# MIMXRT1042 register map
Vendor: nxp.com; File version: 1.0
CPU: CM7 r0p1, little endian, MPU, FPU, VTOR, 4 interrupt priority bits
Registers are 32-bit, read-write, reset 0x0 unless marked. A register's access mark holds for its fields unless they carry their own. Offsets are from the block's base; [hi:lo] are bit positions; {n}, {i} and the like mark numbered series; 'fields as' and 'values as' point back to an identical list.

## MPU — Memory Protection Unit
Base 0xE000ED90
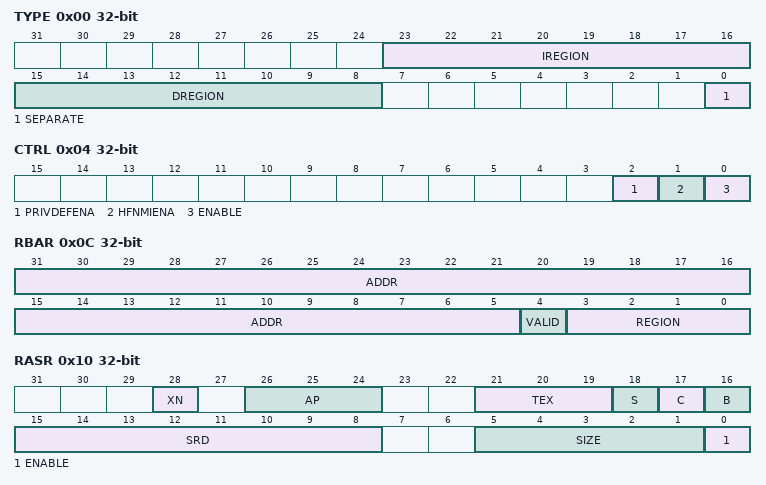
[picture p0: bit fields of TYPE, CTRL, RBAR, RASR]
0x00 TYPE ro reset not defined — The MPU Type Register indicates how many regions the MPU support. Software can use it to determine if the processor implements an MPU.
  [23:16] IREGION — Instruction region. RAZ. Armv7-M only supports a unified MPU.
  [15:8] DREGION — Number of regions supported by the MPU. If this field reads-as-zero the processor does not implement an MPU.
  [0] SEPARATE — Indicates support for separate instruction and data address maps. RAZ. Armv7-M only supports a unified MPU
0x04 CTRL — MPU Control Register.
  [2] PRIVDEFENA
    0=ENABLE (Disables the default memory map. Any instruction or data access that does not access a defined region faults.); 1=DISABLE (Enables the default memory map as a background region for privileged access. The background region acts as region number -1. All memory regions configured in the MPU take priority over the default memory map.)
  [1] HFNMIENA — Controls whether handlers executing with priority less than 0 access memory with the MPU enabled or with the MPU disabled.
    0=DISABLE (Disables the MPU for these handlers.); 1=ENABLE (Use the MPU for memory accesses by these handlers.)
  [0] ENABLE — Enables the MPU.
    0=MPU_DISABLE (The MPU is disabled.); 1=MPU_ENABLED (The MPU is enabled.)
0x08 RNR reset not defined — MPU Region Number Register.
  [7:0] REGION — Indicates the memory region accessed by MPU_RBAR and MPU_RASR.
0x0C RBAR reset not defined — MPU Region Base Address Register.
  [31:5] ADDR — Base address of the region.
  [4] VALID — On writes, indicates whether the region to update is specified by MPU_RNR.REGION, or by the REGION value specified in this write. When using the REGION value specified by this write, MPU_RNR.REGION is updated to this value.
    0=IGNORE_RBAR_REGION (Apply the base address update to the region specified by MPU_RNR.REGION. The REGION field value is ignored.); 1=USE_RBAR_REGION (Update MPU_RNR.REGION to the value obtained by zero extending the REGION value specified in this write, and apply the base address update to this region.)
  [3:0] REGION — On writes, can specify the number of the region to update. On reads, returns bits[3:0] of MPU_RNR.
0x10 RASR reset not defined — MPU Region Attribute and Size Register.
  [28] XN — The XN bit is an Execute Never bit, that indicates whether the processor can execute instructions from the region.
    0=EXECUTE (Execution of an instruction fetched from this region permitted.); 1=EXECUTE_NEVER (Execution of an instruction fetched from this region not permitted.)
  [26:24] AP — The AP[2:0] bits indicate the access and privilege properties of the region.
    0=NO_ACCESS (Any access generates a permission fault.); 1=PRIVILEGED_ACCESS (Privileged access only.); 2=UNPRIVILEGED_READ_ACCESS (Any unprivileged write generates a permission fault (Priviledge read/write, unprivileged read-only).); 3=FULL_ACCESS; 5=PRIVILEGED_READ_ONLY (Privileged read-only access.); 6=READ_ONLY (Privileged and unprivileged read-only access.); 7=READ_ONLY_2 (Privileged and unprivileged read-only access.)
  [21:19] TEX — Memory type attribute TEX. The TEX[2:0], C, and B bits together indicate the memory type of the region
  [18] S — For Normal memory regions, the S bit indicates whether the region is shareable. For Strongly-ordered and Device memory, the S bit is ignored.
    0=NON_SHAREABLE (Non-shareable memory.); 1=SHAREABLE (Shareable memory.)
  [17] C — Memory type attribute C. The TEX[2:0], C, and B bits together indicate the memory type of the region.
  [16] B — Memory type attribute B. The TEX[2:0], C, and B bits together indicate the memory type of the region.
  [15:8] SRD — Subregion Disable. For regions of 256 bytes or larger, each bit of this field controls whether one of the eight equal subregions is enabled. SRD[0-7]=0 - subregion enabled. SRD[0-7]=1 - subregion disabled.
  [5:1] SIZE — Indicates the region size. The region size, in bytes, is 2**(SIZE+1). SIZE field values less than 4 are reserved, because the smallest supported region size is 32 bytes.
  [0] ENABLE — Enables this region.
    0=DISABLED (When the MPU is enabled, this region is disabled.); 1=ENABLED (When the MPU is enabled, this region is enabled.)
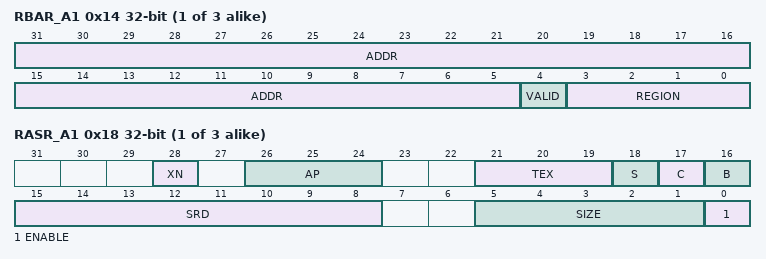
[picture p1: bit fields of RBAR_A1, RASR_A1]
{0xC+8i} RBAR_A{i} reset not defined (i=1..3) — MPU Region Base Address Register.
  fields as RBAR
{0x10+8i} RASR_A{i} reset not defined (i=1..3) — MPU Region Attribute and Size Register.
  fields as RASR
